# STM32C071 register map
File version: 1.1
CPU: CM0+ r0p0, little endian, MPU, no FPU, 2 interrupt priority bits
Registers are 32-bit, read-write, reset 0x0 unless marked. A register's access mark holds for its fields unless they carry their own. Offsets are from the block's base; [hi:lo] are bit positions; {n}, {i} and the like mark numbered series.

## GPIOA — GPIOA address block description
Base 0x50000000
Same registers: GPIOB 0x50000400, GPIOC 0x50000800, GPIOD 0x50000C00, GPIOF 0x50001400
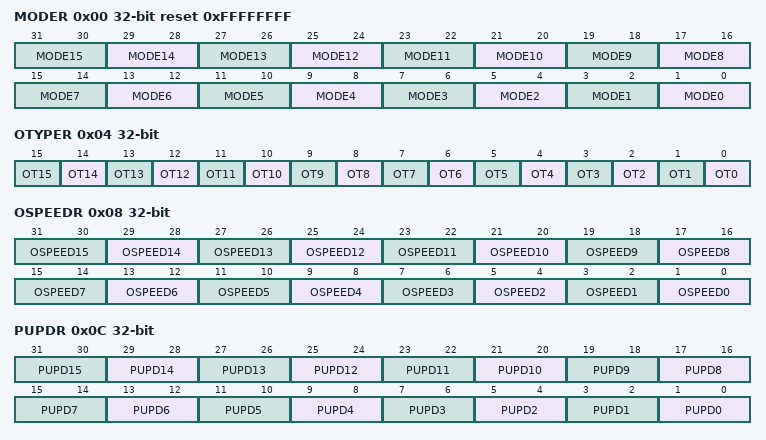
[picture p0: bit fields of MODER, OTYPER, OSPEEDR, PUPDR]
0x00 MODER reset 0xFFFFFFFF — GPIO port mode register
  [2n+1:2n] MODE{n} (n=0..15) — Port x configuration pin {n}
    0=Input mode; 1=Output (General purpose output mode); 2=Alternate function mode; 3=Analog mode
0x04 OTYPER — GPIO port output type register
  [n] OT{n} (n=0..15) — Port x configuration pin {n}
    0=PushPull (Output push-pull (reset state)); 1=OpenDrain (Output open-drain)
0x08 OSPEEDR — GPIO port output speed register
  [2n+1:2n] OSPEED{n} (n=0..15) — Port x configuration pin {n}
    0=LowSpeed; 1=MediumSpeed; 2=HighSpeed; 3=VeryHighSpeed
0x0C PUPDR — GPIO port pull-up/pull-down register
  [2n+1:2n] PUPD{n} (n=0..15) — Port x configuration pin {n}
    0=Floating (No pull-up, pull-down); 1=PullUp; 2=PullDown
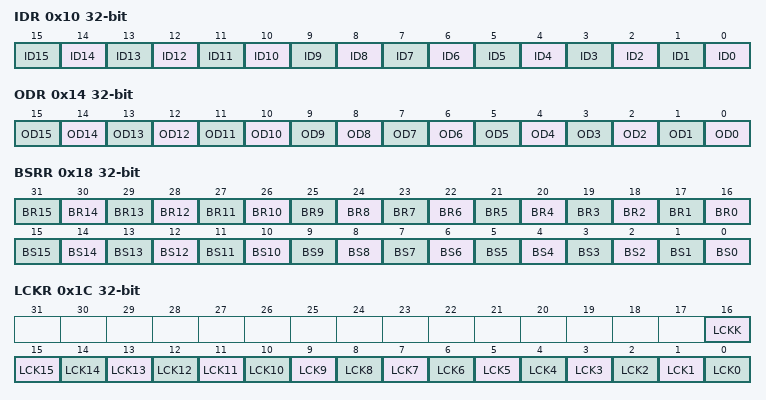
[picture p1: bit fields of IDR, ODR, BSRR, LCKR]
0x10 IDR ro (reset mask 0xFFFF0000) — GPIO port input data register
  [n] ID{n} (n=0..15) — Port input data pin {n}
    0=Low (Input is logic low); 1=High (Input is logic high)
0x14 ODR — GPIO port output data register
  [n] OD{n} (n=0..15) — Port output data pin {n}
    0=Low (Set output to logic low); 1=High (Set output to logic high)
0x18 BSRR wo — GPIO port bit set/reset register
  [n+16] BR{n} (n=0..15) — Port x reset pin {n}
    1=Resets the corresponding ODx bit
  [n] BS{n} (n=0..15) — Port x set pin {n}
    1=Set (Sets the corresponding ODx bit)
0x1C LCKR — GPIO port configuration lock register
  [16] LCKK — Lock key This bit can be read any time. It can only be modified using the lock key write sequence. LOCK key write sequence: WR LCKR[16] = 1 + LCKR[15:0] WR LCKR[16] = 0 + LCKR[15:0] WR LCKR[16] = 1 + LCKR[15:0] RD LCKR RD LCKR[16] = 1 (this read operation is optional but it confirms that the lock is active) Note: During the LOCK key write sequence, the value of LCK[15:0] must not change. Note: Any error in the lock sequence aborts the lock. Note: After the first lock sequence on any bit of the port, any read access on the LCKK bit returns 1 until the next MCU reset or peripheral reset.
    0=NotActive (Port configuration lock key not active); 1=Active (Port configuration lock key active)
  [n] LCK{n} (n=0..15) — Port x lock pin {n}
    0=Unlocked (Port configuration not locked); 1=Locked (Port configuration locked)
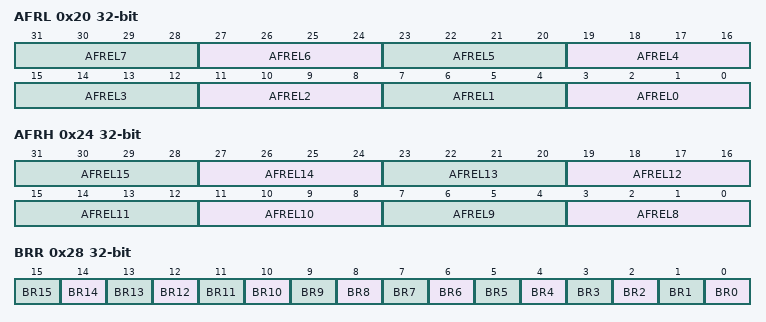
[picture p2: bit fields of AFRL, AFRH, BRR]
0x20 AFRL — GPIO alternate function low register
  [3:0] AFR{x} (x=EL0,EL1,EL2,EL3,EL4,EL5,EL6,EL7; step 4) — Alternate function selection for port x pin y These bits are written by software to configure alternate function I/Os
    {v}=AF{v} (v=0..15)
0x24 AFRH — GPIO alternate function high register
  [3:0] AFR{x} (x=EL8,EL9,EL10,EL11,EL12,EL13,EL14,EL15; step 4) — Alternate function selection for port x, I/O y These bits are written by software to configure alternate function I/Os
    {v}=AF{v} (v=0..15)
0x28 BRR wo — GPIO port bit reset register
  [n] BR{n} (n=0..15) — Port x reset pin {n}
    0=No action on the corresponding ODx bit; 1=Reset the ODx bit

## WWDG — WWDG address block description
Base 0x40002C00
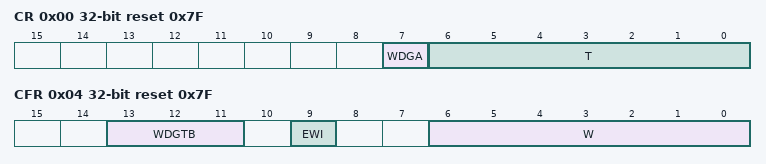
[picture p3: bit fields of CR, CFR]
0x00 CR reset 0x7F — WWDG control register
  [7] WDGA — Activation bit This bit is set by software and only cleared by hardware after a reset. When WDGA = 1, the watchdog can generate a reset.
    0=Disabled (Watchdog disabled); 1=Enabled (Watchdog enabled)
  [6:0] T — 7-bit counter (MSB to LSB) These bits contain the value of the watchdog counter, decremented every (4096 x 2<sup>WDGTB[2:0]</sup>) PCLK cycles. A reset is produced when it is decremented from 0x40 to 0x3F (T6 becomes cleared).
0x04 CFR reset 0x7F — WWDG configuration register
  [13:11] WDGTB — Timer base The timebase of the prescaler can be modified as follows:
    0=Div1 (Counter clock (PCLK1 div 4096) div 1); 1=Div2 (Counter clock (PCLK1 div 4096) div 2); 2=Div4 (Counter clock (PCLK1 div 4096) div 4); 3=Div8 (Counter clock (PCLK1 div 4096) div 8); 4=Div16 (Counter clock (PCLK1 div 4096) div 16); 5=Div32 (Counter clock (PCLK1 div 4096) div 32); 6=Div64 (Counter clock (PCLK1 div 4096) div 64); 7=Div128 (Counter clock (PCLK1 div 4096) div 128)
  [9] EWI — Early wake-up interrupt enable Set by software and cleared by hardware after a reset. When set, an interrupt occurs whenever the counter reaches the value 0x40.
    on write: 1=Enable (interrupt occurs whenever the counter reaches the value 0x40)
  [6:0] W — 7-bit window value These bits contain the window value to be compared with the down-counter.
0x08 SR — WWDG status register
  [0] EWIF write-0-clears — Early wake-up interrupt flag This bit is set by hardware when the counter has reached the value 0x40. It must be cleared by software by writing 0. Writing 1 has no effect. This bit is also set if the interrupt is not enabled.
    on read: 0=Finished (The EWI Interrupt Service Routine has been serviced); 1=Pending (The EWI Interrupt Service Routine has been triggered) | on write: 0=Finished (The EWI Interrupt Service Routine has been serviced)
